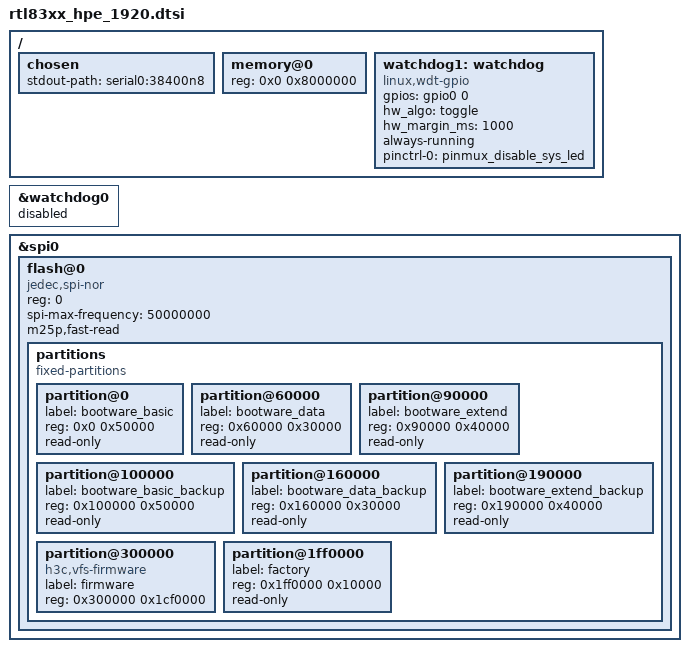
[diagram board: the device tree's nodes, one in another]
// SPDX-License-Identifier: GPL-2.0-or-later OR MIT

#include <dt-bindings/input/input.h>
#include <dt-bindings/gpio/gpio.h>

/ {
	chosen {
		stdout-path = "serial0:38400n8";
	};

	memory@0 {
		device_type = "memory";
		reg = <0x0 0x8000000>;
	};

	watchdog1: watchdog {
		// PT7A7514
		compatible = "linux,wdt-gpio";
		gpios = <&gpio0 0 GPIO_ACTIVE_HIGH>;
		hw_algo = "toggle";
		hw_margin_ms = <1000>;
		always-running;

		pinctrl-names = "default";
		pinctrl-0 = <&pinmux_disable_sys_led>;
	};
};

&watchdog0 {
	status = "disabled";
};

&spi0 {
	status = "okay";

	flash@0 {
		compatible = "jedec,spi-nor";
		reg = <0>;
		spi-max-frequency = <50000000>;
		m25p,fast-read;

		partitions {
			compatible = "fixed-partitions";
			#address-cells = <1>;
			#size-cells = <1>;

			partition@0 {
				label = "bootware_basic";
				reg = <0x0 0x50000>;
				read-only;
			};

			partition@60000 {
				label = "bootware_data";
				reg = <0x60000 0x30000>;
				read-only;
			};

			partition@90000 {
				label = "bootware_extend";
				reg = <0x90000 0x40000>;
				read-only;
			};

			partition@100000 {
				label = "bootware_basic_backup";
				reg = <0x100000 0x50000>;
				read-only;
			};

			partition@160000 {
				label = "bootware_data_backup";
				reg = <0x160000 0x30000>;
				read-only;
			};

			partition@190000 {
				label = "bootware_extend_backup";
				reg = <0x190000 0x40000>;
				read-only;
			};

			partition@300000 {
				label = "firmware";
				compatible = "h3c,vfs-firmware";
				reg = <0x300000 0x1cf0000>;
			};

			partition@1ff0000 {
				label = "factory";
				reg = <0x1ff0000 0x10000>;
				read-only;
			};
		};
	};
};
